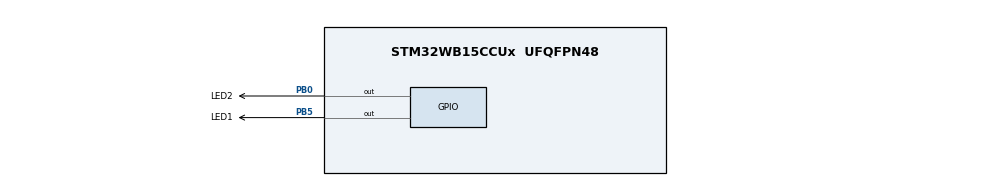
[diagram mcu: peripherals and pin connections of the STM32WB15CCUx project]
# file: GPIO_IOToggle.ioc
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Mcu.Family=STM32WB
Mcu.Name=STM32WB15CCUx
Mcu.Package=UFQFPN48
NVIC.PriorityGroup=NVIC_PRIORITYGROUP_4
PB0.GPIO_Label=LED2
PB0.GPIO_PuPd=GPIO_PULLUP
PB0.GPIO_Speed=GPIO_SPEED_FREQ_HIGH
PB0.PinState=GPIO_PIN_RESET
PB0.Signal=GPIO_Output
PB5.GPIO_Label=LED1
PB5.GPIO_PuPd=GPIO_PULLUP
PB5.GPIO_Speed=GPIO_SPEED_FREQ_HIGH
PB5.Signal=GPIO_Output
ProjectManager.HeapSize=0x200
ProjectManager.StackSize=0x400
ProjectManager.TargetToolchain=EWARM V8
RCC.AHB2CLKDivider=RCC_SYSCLK_DIV2
RCC.AHBFreq_Value=64000000
RCC.APB1Freq_Value=64000000
RCC.APB1TimFreq_Value=64000000
RCC.APB2Freq_Value=64000000
RCC.APB2TimFreq_Value=64000000
RCC.APB3Freq_Value=16000000
RCC.CortexFreq_Value=64000000
RCC.HCLKFreq_Value=64000000
RCC.HSE_VALUE=8000000
RCC.HSI_VALUE=16000000
RCC.LSE_VALUE=32768
RCC.PLLN=32
RCC.SYSCLKFreq_VALUE=64000000
RCC.SYSCLKSource=RCC_SYSCLKSOURCE_PLLCLK
RCC.VCOOutputFreq_Value=128000000
board=custom

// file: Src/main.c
/* USER CODE BEGIN Header */
/**
  ******************************************************************************
  * @file    GPIO/GPIO_IOToggle/Src/main.c
  * @author  MCD Application Team
  * @brief   This example describes how to configure and use GPIOs through
  *          the STM32WBxx HAL API.
  ******************************************************************************
  * @attention
  *
  * Copyright (c) 2019-2021 STMicroelectronics.
  * All rights reserved.
  *
  * This software is licensed under terms that can be found in the LICENSE file
  * in the root directory of this software component.
  * If no LICENSE file comes with this software, it is provided AS-IS.
  *
  ******************************************************************************
  */
/* USER CODE END Header */
#include "main.h"

void SystemClock_Config(void);
void PeriphCommonClock_Config(void);
static void MX_GPIO_Init(void);

int main(void)
{
  /* USER CODE BEGIN 1 */
  /* STM32WBxx HAL library initialization:
       - Configure the Flash prefetch
       - Systick timer is configured by default as source of time base, but user
         can eventually implement his proper time base source (a general purpose
         timer for example or other time source), keeping in mind that Time base
         duration should be kept 1ms since PPP_TIMEOUT_VALUEs are defined and
         handled in milliseconds basis.
       - Set NVIC Group Priority to 4
       - Low Level Initialization
     */
  /* USER CODE END 1 */

  /* MCU Configuration--------------------------------------------------------*/

  /* Reset of all peripherals, Initializes the Flash interface and the Systick. */
  HAL_Init();

  /* Configure the system clock */
  SystemClock_Config();

  /* Configure the peripherals common clocks */
  PeriphCommonClock_Config();

  /* Initialize all configured peripherals */
  MX_GPIO_Init();

  /* Infinite loop */
  while (1)
  {

    /* USER CODE BEGIN 3 */
    HAL_GPIO_TogglePin(LED2_GPIO_Port, LED2_Pin);
    /* Insert delay 100 ms */
    HAL_Delay(100);
    HAL_GPIO_TogglePin(LED1_GPIO_Port, LED1_Pin);
    /* Insert delay 100 ms */
    HAL_Delay(100);

  }
  /* USER CODE END 3 */
}

void SystemClock_Config(void)
{
  RCC_OscInitTypeDef RCC_OscInitStruct = {0};
  RCC_ClkInitTypeDef RCC_ClkInitStruct = {0};

  /** Initializes the RCC Oscillators according to the specified parameters
  * in the RCC_OscInitTypeDef structure.
  */
  RCC_OscInitStruct.OscillatorType = RCC_OSCILLATORTYPE_HSI|RCC_OSCILLATORTYPE_MSI;
  RCC_OscInitStruct.HSIState = RCC_HSI_ON;
  RCC_OscInitStruct.MSIState = RCC_MSI_ON;
  RCC_OscInitStruct.HSICalibrationValue = RCC_HSICALIBRATION_DEFAULT;
  RCC_OscInitStruct.MSICalibrationValue = RCC_MSICALIBRATION_DEFAULT;
  RCC_OscInitStruct.MSIClockRange = RCC_MSIRANGE_6;
  RCC_OscInitStruct.PLL.PLLState = RCC_PLL_ON;
  RCC_OscInitStruct.PLL.PLLSource = RCC_PLLSOURCE_MSI;
  RCC_OscInitStruct.PLL.PLLM = RCC_PLLM_DIV1;
  RCC_OscInitStruct.PLL.PLLN = 32;
  RCC_OscInitStruct.PLL.PLLP = RCC_PLLP_DIV2;
  RCC_OscInitStruct.PLL.PLLR = RCC_PLLR_DIV2;
  RCC_OscInitStruct.PLL.PLLQ = RCC_PLLQ_DIV2;
  if (HAL_RCC_OscConfig(&RCC_OscInitStruct) != HAL_OK)
  {
    Error_Handler();
  }

  /** Configure the SYSCLKSource, HCLK, PCLK1 and PCLK2 clocks dividers
  */
  RCC_ClkInitStruct.ClockType = RCC_CLOCKTYPE_HCLK4|RCC_CLOCKTYPE_HCLK2
                              |RCC_CLOCKTYPE_HCLK|RCC_CLOCKTYPE_SYSCLK
                              |RCC_CLOCKTYPE_PCLK1|RCC_CLOCKTYPE_PCLK2;
  RCC_ClkInitStruct.SYSCLKSource = RCC_SYSCLKSOURCE_PLLCLK;
  RCC_ClkInitStruct.AHBCLKDivider = RCC_SYSCLK_DIV1;
  RCC_ClkInitStruct.APB1CLKDivider = RCC_HCLK_DIV1;
  RCC_ClkInitStruct.APB2CLKDivider = RCC_HCLK_DIV1;
  RCC_ClkInitStruct.AHBCLK2Divider = RCC_SYSCLK_DIV2;
  RCC_ClkInitStruct.AHBCLK4Divider = RCC_SYSCLK_DIV1;

  if (HAL_RCC_ClockConfig(&RCC_ClkInitStruct, FLASH_LATENCY_3) != HAL_OK)
  {
    Error_Handler();
  }
}

void PeriphCommonClock_Config(void)
{
  RCC_PeriphCLKInitTypeDef PeriphClkInitStruct = {0};

  /** Initializes the peripherals clock
  */
  PeriphClkInitStruct.PeriphClockSelection = RCC_PERIPHCLK_SMPS;
  PeriphClkInitStruct.SmpsClockSelection = RCC_SMPSCLKSOURCE_HSI;
  PeriphClkInitStruct.SmpsDivSelection = RCC_SMPSCLKDIV_RANGE1;

  if (HAL_RCCEx_PeriphCLKConfig(&PeriphClkInitStruct) != HAL_OK)
  {
    Error_Handler();
  }
}

static void MX_GPIO_Init(void)
{
  GPIO_InitTypeDef GPIO_InitStruct = {0};

  /* GPIO Ports Clock Enable */
  __HAL_RCC_GPIOB_CLK_ENABLE();

  /*Configure GPIO pin Output Level */
  HAL_GPIO_WritePin(GPIOB, LED2_Pin|LED1_Pin, GPIO_PIN_RESET);

  /*Configure GPIO pins : LED2_Pin LED1_Pin */
  GPIO_InitStruct.Pin = LED2_Pin|LED1_Pin;
  GPIO_InitStruct.Mode = GPIO_MODE_OUTPUT_PP;
  GPIO_InitStruct.Pull = GPIO_PULLUP;
  GPIO_InitStruct.Speed = GPIO_SPEED_FREQ_HIGH;
  HAL_GPIO_Init(GPIOB, &GPIO_InitStruct);

}

void Error_Handler(void)
{
  while(1)
  {
  }
}
